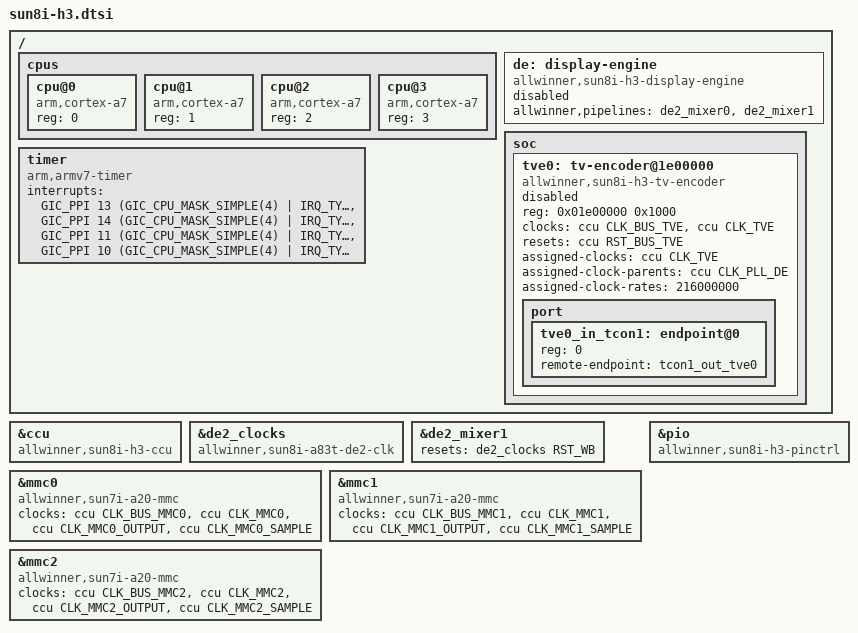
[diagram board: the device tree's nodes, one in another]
/*
 * Copyright (C) 2015 Jens Kuske <jenskuske@gmail.com>
 *
 * This file is dual-licensed: you can use it either under the terms
 * of the GPL or the X11 license, at your option. Note that this dual
 * licensing only applies to this file, and not this project as a
 * whole.
 *
 *  a) This file is free software; you can redistribute it and/or
 *     modify it under the terms of the GNU General Public License as
 *     published by the Free Software Foundation; either version 2 of the
 *     License, or (at your option) any later version.
 *
 *     This file is distributed in the hope that it will be useful,
 *     but WITHOUT ANY WARRANTY; without even the implied warranty of
 *     MERCHANTABILITY or FITNESS FOR A PARTICULAR PURPOSE.  See the
 *     GNU General Public License for more details.
 *
 * Or, alternatively,
 *
 *  b) Permission is hereby granted, free of charge, to any person
 *     obtaining a copy of this software and associated documentation
 *     files (the "Software"), to deal in the Software without
 *     restriction, including without limitation the rights to use,
 *     copy, modify, merge, publish, distribute, sublicense, and/or
 *     sell copies of the Software, and to permit persons to whom the
 *     Software is furnished to do so, subject to the following
 *     conditions:
 *
 *     The above copyright notice and this permission notice shall be
 *     included in all copies or substantial portions of the Software.
 *
 *     THE SOFTWARE IS PROVIDED "AS IS", WITHOUT WARRANTY OF ANY KIND,
 *     EXPRESS OR IMPLIED, INCLUDING BUT NOT LIMITED TO THE WARRANTIES
 *     OF MERCHANTABILITY, FITNESS FOR A PARTICULAR PURPOSE AND
 *     NONINFRINGEMENT. IN NO EVENT SHALL THE AUTHORS OR COPYRIGHT
 *     HOLDERS BE LIABLE FOR ANY CLAIM, DAMAGES OR OTHER LIABILITY,
 *     WHETHER IN AN ACTION OF CONTRACT, TORT OR OTHERWISE, ARISING
 *     FROM, OUT OF OR IN CONNECTION WITH THE SOFTWARE OR THE USE OR
 *     OTHER DEALINGS IN THE SOFTWARE.
 */

#include "sunxi-h3-h5.dtsi"
#include <dt-bindings/clock/sun8i-de2.h>
#include <dt-bindings/reset/sun8i-de2.h>

/ {
	cpus {
		#address-cells = <1>;
		#size-cells = <0>;

		cpu@0 {
			compatible = "arm,cortex-a7";
			device_type = "cpu";
			reg = <0>;
		};

		cpu@1 {
			compatible = "arm,cortex-a7";
			device_type = "cpu";
			reg = <1>;
		};

		cpu@2 {
			compatible = "arm,cortex-a7";
			device_type = "cpu";
			reg = <2>;
		};

		cpu@3 {
			compatible = "arm,cortex-a7";
			device_type = "cpu";
			reg = <3>;
		};
	};

	de: display-engine {
		compatible = "allwinner,sun8i-h3-display-engine";
		allwinner,pipelines = <&de2_mixer0>,
				      <&de2_mixer1>;
		status = "disabled";
	};

	soc {
		tve0: tv-encoder@1e00000 {
			compatible = "allwinner,sun8i-h3-tv-encoder";
			reg = <0x01e00000 0x1000>;
			clocks = <&ccu CLK_BUS_TVE>, <&ccu CLK_TVE>;
			clock-names = "bus", "mod";
			resets = <&ccu RST_BUS_TVE>;
			status = "disabled";

			assigned-clocks = <&ccu CLK_TVE>;
			assigned-clock-parents = <&ccu CLK_PLL_DE>;
			assigned-clock-rates = <216000000>;

			port {
				#address-cells = <1>;
				#size-cells = <0>;

				tve0_in_tcon1: endpoint@0 {
					reg = <0>;
					remote-endpoint = <&tcon1_out_tve0>;
				};
			};
		};
	};

	timer {
		compatible = "arm,armv7-timer";
		interrupts = <GIC_PPI 13 (GIC_CPU_MASK_SIMPLE(4) | IRQ_TYPE_LEVEL_LOW)>,
			     <GIC_PPI 14 (GIC_CPU_MASK_SIMPLE(4) | IRQ_TYPE_LEVEL_LOW)>,
			     <GIC_PPI 11 (GIC_CPU_MASK_SIMPLE(4) | IRQ_TYPE_LEVEL_LOW)>,
			     <GIC_PPI 10 (GIC_CPU_MASK_SIMPLE(4) | IRQ_TYPE_LEVEL_LOW)>;
	};
};

&ccu {
	compatible = "allwinner,sun8i-h3-ccu";
};

&de2_clocks {
	compatible = "allwinner,sun8i-a83t-de2-clk";
};

&de2_mixer1 {
	resets = <&de2_clocks RST_WB>;
};

&mmc0 {
	compatible = "allwinner,sun7i-a20-mmc";
	clocks = <&ccu CLK_BUS_MMC0>,
		 <&ccu CLK_MMC0>,
		 <&ccu CLK_MMC0_OUTPUT>,
		 <&ccu CLK_MMC0_SAMPLE>;
	clock-names = "ahb",
		      "mmc",
		      "output",
		      "sample";
};

&mmc1 {
	compatible = "allwinner,sun7i-a20-mmc";
	clocks = <&ccu CLK_BUS_MMC1>,
		 <&ccu CLK_MMC1>,
		 <&ccu CLK_MMC1_OUTPUT>,
		 <&ccu CLK_MMC1_SAMPLE>;
	clock-names = "ahb",
		      "mmc",
		      "output",
		      "sample";
};

&mmc2 {
	compatible = "allwinner,sun7i-a20-mmc";
	clocks = <&ccu CLK_BUS_MMC2>,
		 <&ccu CLK_MMC2>,
		 <&ccu CLK_MMC2_OUTPUT>,
		 <&ccu CLK_MMC2_SAMPLE>;
	clock-names = "ahb",
		      "mmc",
		      "output",
		      "sample";
};

&pio {
	compatible = "allwinner,sun8i-h3-pinctrl";
};
